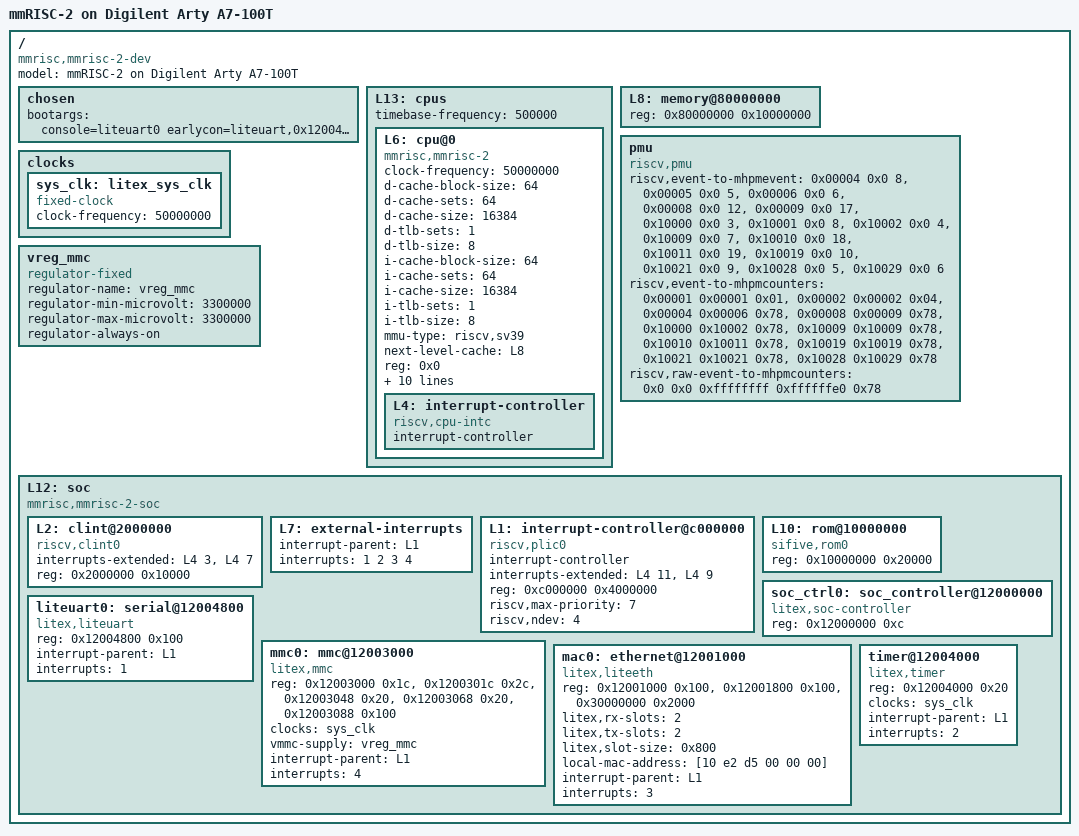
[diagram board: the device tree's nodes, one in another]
/* Device tree for mmRISC-2 on the Digilent Arty A7-100T.
 *
 * Taken from the working Rocket build of the same board and changed only
 * where the CPU differs: the memory map, the peripherals and their
 * interrupt numbers came out of LiteX byte for byte the same (see
 * LitexSystem/docs/BRINGUP.md).
 *
 * timebase-frequency must match CLINT_TICK_DIV of the hardware: mtime
 * counts one step every 100 cycles of the 50 MHz clock.
 *
 * console=liteuart0, not console=liteuart: the kernel also hands the
 * console= value to the early console setup, and a bare "liteuart" matches
 * the LiteUART early console, which then started at address 0 ("Malformed
 * early option 'console'"). The index keeps it from matching.
 *
 * With Ethernet (scripts/build_soc.sh --with-ethernet) LiteX puts ethmac and
 * ethphy first among the CSRs, so every block after them moved up by 0x1000,
 * and the interrupts are uart 0, timer0 1, ethmac 2, sdcard 3 in LiteX
 * numbers, PLIC sources 1..4 (LitexSystem/build/csr.csv).
 */
/dts-v1/;

/ {
	#address-cells = <1>;
	#size-cells = <1>;
	compatible = "mmrisc,mmrisc-2-dev";
	model = "mmRISC-2 on Digilent Arty A7-100T";
	chosen {
		bootargs = "console=liteuart0 earlycon=liteuart,0x12004800 swiotlb=noforce rootwait root=/dev/mmcblk0p2 rootfstype=ext4 rw";
	};
	L13: cpus {
		#address-cells = <1>;
		#size-cells = <0>;
		timebase-frequency = <500000>;
		L6: cpu@0 {
			clock-frequency = <50000000>;
			compatible = "mmrisc,mmrisc-2", "riscv";
			d-cache-block-size = <64>;
			d-cache-sets = <64>;
			d-cache-size = <16384>;
			d-tlb-sets = <1>;
			d-tlb-size = <8>;
			device_type = "cpu";
			i-cache-block-size = <64>;
			i-cache-sets = <64>;
			i-cache-size = <16384>;
			i-tlb-sets = <1>;
			i-tlb-size = <8>;
			mmu-type = "riscv,sv39";
			next-level-cache = <&L8>;
			reg = <0x0>;
			/* The extensions one by one, as Linux wants them now (without
			 * them it falls back to riscv,isa and warns). Only what the
			 * core has: the counters are cycle, time and instret (Zicntr),
			 * and since 2026-10 hpmcounter3-6 (Zihpm) with the overflow
			 * interrupt of Sscofpmf and the level filters of Smcntrpmf
			 * for cycle / instret (decision 69; the pmu node below
			 * tells OpenSBI their events). Zba and Zbb since
			 * 2026-10 (CPU_CORE_SPEC.md 2.1): with them Linux patches in
			 * its Zbb string functions at boot. Sstc since 2026-10 too
			 * (decision 66): Linux then sets its timer in stimecmp
			 * instead of asking OpenSBI. Zicond, Zihintpause and
			 * Zihintntl since 2026-10 (decision 68): PAUSE lets Linux's
			 * cpu_relax() use the hint. riscv,isa stays for OpenSBI and
			 * older software.
			 * Use this tree only with a bitstream that has all of them. */
			riscv,isa = "rv64imafdc_zicntr_zicond_zicsr_zifencei_zihintntl_zihintpause_zihpm_zba_zbb_smcntrpmf_sscofpmf_sstc";
			riscv,isa-base = "rv64i";
			riscv,isa-extensions = "i", "m", "a", "f", "d", "c",
				"zicntr", "zicond", "zicsr", "zifencei", "zihintntl",
				"zihintpause", "zihpm", "zba", "zbb", "smcntrpmf", "sscofpmf",
				"sstc";
			riscv,pmpgranularity = <4>;
			riscv,pmpregions = <8>;
			status = "okay";
			tlb-split;
			L4: interrupt-controller {
				#interrupt-cells = <1>;
				compatible = "riscv,cpu-intc";
				interrupt-controller;
			};
		};
	};
	L8: memory@80000000 {
		device_type = "memory";
		reg = <0x80000000 0x10000000>; /* 256MB (Arty A7-100T, MT41K128M16 x2) */
	};
	/* The PMU for OpenSBI's SBI PMU extension, through which Linux's perf
	 * uses the counters (CPU_CORE_SPEC.md decision 69). hpmcounter3-6
	 * (map 0x78) count any event; the value for mhpmevent is the event
	 * number of the core:
	 *    1 cycles               7 I$ misses           13 load use cycles
	 *    2 instructions         8 D$ misses           14 MDU / FPU wait cycles
	 *    3 loads retired        9 ITLB misses (walks) 15 exceptions
	 *    4 stores retired      10 DTLB misses (walks) 16 interrupts
	 *    5 cond. branches      11 D$ wait cycles      17 back end stall cycles
	 *    6 wrong guesses       12 front end empty cycles
	 * Generic events (type 0) and cache events (type 1: cache << 3 |
	 * op << 1 | result) map onto them; any of them is also a raw event
	 * (perf stat -e r8 = D$ misses). cycles and instructions are the
	 * fixed counters 0 and 2. */
	pmu {
		compatible = "riscv,pmu";
		riscv,event-to-mhpmevent =
			<0x00004 0x0 8>,	/* cache-misses: D$ misses */
			<0x00005 0x0 5>,	/* branch-instructions */
			<0x00006 0x0 6>,	/* branch-misses */
			<0x00008 0x0 12>,	/* stalled-cycles-frontend */
			<0x00009 0x0 17>,	/* stalled-cycles-backend */
			<0x10000 0x0 3>,	/* L1-dcache-loads */
			<0x10001 0x0 8>,	/* L1-dcache-load-misses (every fill) */
			<0x10002 0x0 4>,	/* L1-dcache-stores */
			<0x10009 0x0 7>,	/* L1-icache-load-misses */
			<0x10010 0x0 18>,	/* LLC-loads: L2 reads (L1 fills) */
			<0x10011 0x0 19>,	/* LLC-load-misses: L2 misses */
			<0x10019 0x0 10>,	/* dTLB-load-misses */
			<0x10021 0x0 9>,	/* iTLB-load-misses */
			<0x10028 0x0 5>,	/* branch-loads */
			<0x10029 0x0 6>;	/* branch-load-misses */
		/* cycles and instructions on their fixed counters only: listed
		 * so that OpenSBI reports them (SBI 3.0 event info, which
		 * Linux asks at boot), and with Smcntrpmf the fixed counters
		 * take the level filters, so no hpmcounter is spent on them */
		riscv,event-to-mhpmcounters =
			<0x00001 0x00001 0x01>,
			<0x00002 0x00002 0x04>,
			<0x00004 0x00006 0x78>,
			<0x00008 0x00009 0x78>,
			<0x10000 0x10002 0x78>,
			<0x10009 0x10009 0x78>,
			<0x10010 0x10011 0x78>,
			<0x10019 0x10019 0x78>,
			<0x10021 0x10021 0x78>,
			<0x10028 0x10029 0x78>;
		riscv,raw-event-to-mhpmcounters =
			<0x0 0x0 0xffffffff 0xffffffe0 0x78>;
	};
	clocks {
		sys_clk: litex_sys_clk {
			#clock-cells = <0>;
			compatible = "fixed-clock";
			clock-frequency = <50000000>;
		};
	};
	vreg_mmc: vreg_mmc {
		compatible = "regulator-fixed";
		regulator-name = "vreg_mmc";
		regulator-min-microvolt = <3300000>;
		regulator-max-microvolt = <3300000>;
		regulator-always-on;
	};
	L12: soc {
		#address-cells = <1>;
		#size-cells = <1>;
		compatible = "mmrisc,mmrisc-2-soc", "simple-bus";
		ranges;
		L2: clint@2000000 {
			compatible = "riscv,clint0";
			interrupts-extended = <&L4 3 &L4 7>;
			reg = <0x2000000 0x10000>;
			reg-names = "control";
		};
		L7: external-interrupts {
			interrupt-parent = <&L1>;
			interrupts = <1 2 3 4>;
		};
		L1: interrupt-controller@c000000 {
			#interrupt-cells = <1>;
			compatible = "riscv,plic0";
			interrupt-controller;
			interrupts-extended = <&L4 11 &L4 9>;
			reg = <0xc000000 0x4000000>;
			reg-names = "control";
			riscv,max-priority = <7>;
			riscv,ndev = <4>;
		};
		L10: rom@10000000 {
			compatible = "sifive,rom0";
			reg = <0x10000000 0x20000>;
			reg-names = "mem";
		};
		soc_ctrl0: soc_controller@12000000 {
			compatible = "litex,soc-controller";
			reg = <0x12000000 0xc>;
		};
		liteuart0: serial@12004800 {
			compatible = "litex,liteuart";
			reg = <0x12004800 0x100>;
			interrupt-parent = <&L1>;
			interrupts = <1>;
		};
		mmc0: mmc@12003000 {
			compatible = "litex,mmc";
			reg = <0x12003000 0x1c>,
				<0x1200301c 0x2c>,
				<0x12003048 0x20>,
				<0x12003068 0x20>,
				<0x12003088 0x100>;
			reg-names = "phy", "core", "reader", "writer", "irq";
			clocks = <&sys_clk>;
			vmmc-supply = <&vreg_mmc>;
			interrupt-parent = <&L1>;
			interrupts = <4>;
		};
		/* LiteEth: the MAC CSRs, the PHY CSRs (MDIO, which the driver
		 * does not use: it takes the link as up) and the packet buffers,
		 * 2 RX slots then 2 TX slots of 2 KiB, below MEM_BASE so the
		 * CPU does not cache them. The MAC address is the one the BIOS
		 * uses, so DHCP gives both the same IP. */
		mac0: ethernet@12001000 {
			compatible = "litex,liteeth";
			reg = <0x12001000 0x100>,
				<0x12001800 0x100>,
				<0x30000000 0x2000>;
			reg-names = "mac", "mdio", "buffer";
			litex,rx-slots = <2>;
			litex,tx-slots = <2>;
			litex,slot-size = <0x800>;
			local-mac-address = [10 e2 d5 00 00 00];
			interrupt-parent = <&L1>;
			interrupts = <3>;
		};
		timer@12004000 {
			compatible = "litex,timer";
			reg = <0x12004000 0x20>;
			clocks = <&sys_clk>;
			interrupt-parent = <&L1>;
			interrupts = <2>;
		};
	};
};
